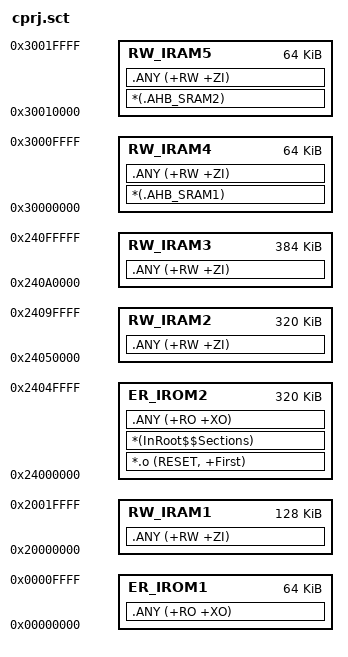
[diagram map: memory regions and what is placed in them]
; *************************************************************
; *** Scatter-Loading Description File generated by uVision ***
; *************************************************************

LR_IROM2 0x24000000 0x00050000  {    ; load region size_region
  ER_IROM2 0x24000000 0x00050000  {  ; load address = execution address
   *.o (RESET, +First)
   *(InRoot$$Sections)
   .ANY (+RO +XO)
  }
  RW_IRAM1 0x20000000 0x00020000  {
   .ANY (+RW +ZI)
  }
  RW_IRAM2 0x24050000 0x00050000  {
   .ANY (+RW +ZI)
  }
  RW_IRAM3 0x240A0000 0x00060000  {
   .ANY (+RW +ZI)
  }
  RW_IRAM4 0x30000000 0x00010000  {
   *(.AHB_SRAM1)
   .ANY (+RW +ZI)
  }
  RW_IRAM5 0x30010000 0x00010000  {
   *(.AHB_SRAM2)
   .ANY (+RW +ZI)
  }
}

LR_IROM1 0x00000000 0x00010000  {
  ER_IROM1 0x00000000 0x00010000  {  ; load address = execution address
   .ANY (+RO +XO)
  }
}
